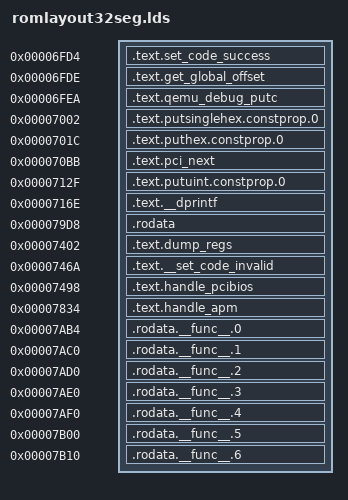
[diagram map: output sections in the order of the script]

/* DO NOT EDIT!  This is an autogenerated file.  See scripts/layoutrom.py. */
OUTPUT_FORMAT("elf32-i386")
OUTPUT_ARCH("i386")
SECTIONS
{
DebugOutputPort = 0x6e0a ;
MaxPCIBus = 0x636c ;
entry_pcibios32 = 0xcd60 ;
PirAddr = 0x6368 ;
entry_apm16 = 0xcced ;
entry_apm32 = 0xcd2e ;
acpi_pm1a_cnt = 0x6364 ;
.text.set_code_success 0x6fd4 : { *(.text.set_code_success) }
.text.get_global_offset 0x6fde : { *(.text.get_global_offset) }
.text.qemu_debug_putc 0x6fea : { *(.text.qemu_debug_putc) }
.text.putsinglehex.constprop.0 0x7002 : { *(.text.putsinglehex.constprop.0) }
.text.puthex.constprop.0 0x701c : { *(.text.puthex.constprop.0) }
.text.pci_next 0x70bb : { *(.text.pci_next) }
.text.putuint.constprop.0 0x712f : { *(.text.putuint.constprop.0) }
.text.__dprintf 0x716e : { *(.text.__dprintf) }
.rodata 0x79d8 : { *(.rodata) }
.text.dump_regs 0x7402 : { *(.text.dump_regs) }
.text.__set_code_invalid 0x746a : { *(.text.__set_code_invalid) }
.text.handle_pcibios 0x7498 : { *(.text.handle_pcibios) }
.text.handle_apm 0x7834 : { *(.text.handle_apm) }
.rodata.__func__.0 0x7ab4 : { *(.rodata.__func__.0) }
.rodata.__func__.1 0x7ac0 : { *(.rodata.__func__.1) }
.rodata.__func__.2 0x7ad0 : { *(.rodata.__func__.2) }
.rodata.__func__.3 0x7ae0 : { *(.rodata.__func__.3) }
.rodata.__func__.4 0x7af0 : { *(.rodata.__func__.4) }
.rodata.__func__.5 0x7b00 : { *(.rodata.__func__.5) }
.rodata.__func__.6 0x7b10 : { *(.rodata.__func__.6) }


        /* Discard regular data sections to force a link error if
         * code attempts to access data not marked with VAR16 (or other
         * appropriate macro)
         */
        /DISCARD/ : {
                *(.text*) *(.data*) *(.bss*) *(.rodata*)
                *(COMMON) *(.discard*) *(.eh_frame) *(.note*)
                }
}
